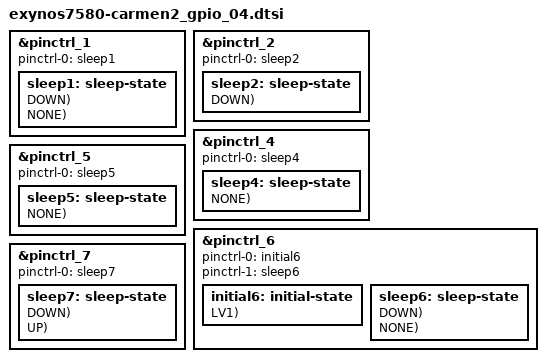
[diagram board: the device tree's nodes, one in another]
/*
 * Copyright (c) 2014 Samsung Electronics Co., Ltd.
 *		http://www.samsung.com
 *
 * This program is free software; you can redistribute it and/or modify
 * it under the terms of the GNU General Public License version 2 as
 * published by the Free Software Foundation.
*/

// Support Carmen2 HW REV02 (b0010)

#include "exynos_gpio_config_macros.dtsi"

// 0x110B0000(AUD): gpz0 ~ gpz3
&pinctrl_1 {
	pinctrl-names = "sleep";
	pinctrl-0 = <&sleep1>;
	sleep1: sleep-state {
		PIN_SLP(gpz0-0, INPUT, DOWN);	/* BT_PCM_SYNC */
		PIN_SLP(gpz0-1, INPUT, DOWN);	/* BT_PCM_CLK */
		PIN_SLP(gpz0-2, INPUT, DOWN);	/* BT_PCM_RXD */
		PIN_SLP(gpz0-3, INPUT, DOWN);	/* BT_PCM_TXD */

		PIN_SLP(gpz1-0, OUT1, NONE);	/* BT_UART_TXD */
		PIN_SLP(gpz1-1, INPUT, NONE);	/* BT_UART_RXD */
		PIN_SLP(gpz1-2, INPUT, NONE);	/* BT_UART_CTS */
		PIN_SLP(gpz1-3, OUT1, NONE);	/* BT_UART_RTS */

		PIN_SLP(gpz2-0, INPUT, DOWN);	/* 2MIC_PCM_SYNC */
		PIN_SLP(gpz2-1, INPUT, DOWN);	/* 2MIC_PCM_CLK */
		PIN_SLP(gpz2-2, INPUT, DOWN);	/* 2MIC_AP_PCM_DI */
		PIN_SLP(gpz2-3, INPUT, DOWN);	/* 2MIC_AP_PCM_DO */

		PIN_SLP(gpz3-0, INPUT, DOWN);	/* NC */
		PIN_SLP(gpz3-1, INPUT, DOWN);	/* NC */
		PIN_SLP(gpz3-2, INPUT, DOWN);	/* 2MIC_CLK_24.576MHZ */
		PIN_SLP(gpz3-3, INPUT, DOWN);	/* NC */
	};
};

// 0x138E0000(ESE): gpc0
&pinctrl_2 {
	pinctrl-names = "sleep";
	pinctrl-0 = <&sleep2>;
	sleep2: sleep-state {
		PIN_SLP(gpc0-0, INPUT, DOWN);	/* BTP_SPI_CLK */
		PIN_SLP(gpc0-1, INPUT, DOWN);	/* BTP_SPI_CS_N */
		PIN_SLP(gpc0-2, INPUT, DOWN);	/* BTP_SPI_MISO */
		PIN_SLP(gpc0-3, INPUT, DOWN);	/* BTP_SPI_MOSI */
	};
};

// 0x104E0000(MIF): gpm0
&pinctrl_4 {
	pinctrl-names = "sleep";
	pinctrl-0 = <&sleep4>;
	sleep4: sleep-state {
		PIN_SLP(gpm0-0, INPUT, NONE);	/* PMIC_SCL_1P8 */
		PIN_SLP(gpm0-1, INPUT, NONE);	/* PMIC_SDA_1P8 */
	};
};

// 0x138C0000(NFC): gpc3
&pinctrl_5 {
	pinctrl-names = "sleep";
	pinctrl-0 = <&sleep5>;
	sleep5: sleep-state {
		PIN_SLP(gpc3-0, INPUT, NONE);	/* NFC_SCL_1P8 */
		PIN_SLP(gpc3-1, INPUT, NONE);	/* NFC_SDA_1P8 */
		PIN_SLP(gpc3-2, PREV, NONE);	/* NFC_EN */
		PIN_SLP(gpc3-3, PREV, NONE);	/* NFC_CLK_REQ */
	};
};

// 0x139C0000(TOP): gpb0~2, gpc1~2, gpc5, gpd0~3, gpe0~1, gpf0~2, etc0
&pinctrl_6 {
	pinctrl-names = "default","sleep";
	pinctrl-0 = <&initial6>;
	pinctrl-1 = <&sleep6>;
	initial6: initial-state {
		PIN_IN(gpd0-0, NONE, LV1);	/* HW_REV0 */
		PIN_IN(gpd0-1, NONE, LV1);	/* HW_REV1 */
		PIN_IN(gpd0-2, NONE, LV1);	/* HW_REV2 */
		PIN_IN(gpd0-3, NONE, LV1);	/* HW_REV3 */
		PIN_OUT_SET(gpd0-5, 0, LV1);    /* LDO26_EN */
	};
	sleep6: sleep-state {
		PIN_SLP(gpb0-0, INPUT, DOWN);	/* AP_UART_RXD */
		PIN_SLP(gpb0-1, INPUT, DOWN);	/* AP_UART_TXD */
		PIN_SLP(gpb0-2, PREV, NONE);	/* SVC_LED_SDA_1P8 */
		PIN_SLP(gpb0-3, PREV, NONE);	/* SVC_LED_SCL_1P8 */
		PIN_SLP(gpb0-4, INPUT, NONE);	/* GPS_RXD */
		PIN_SLP(gpb0-5, OUT0, NONE);	/* GPS_TXD */
		PIN_SLP(gpb0-6, INPUT, NONE);	/* GPS_CTS */
		PIN_SLP(gpb0-7, OUT1, NONE);	/* GPS_RTS */

		PIN_SLP(gpb1-0, INPUT, DOWN);	/* HEALTH_UART_RXD */
		PIN_SLP(gpb1-1, INPUT, DOWN);	/* HEALTH_UART_TXD */

		PIN_SLP(gpb2-0, INPUT, NONE);	/* SHUB_SPI_CLK */
		PIN_SLP(gpb2-1, INPUT, NONE);	/* SHUB_SPI_SS_N */
		PIN_SLP(gpb2-2, INPUT, NONE);	/* SHUB_SPI_MISO */
		PIN_SLP(gpb2-3, INPUT, NONE);	/* SHUB_SPI_MOSI */
		PIN_SLP(gpb2-4, INPUT, DOWN);	/* NC */
		PIN_SLP(gpb2-5, INPUT, DOWN);	/* NC */
		PIN_SLP(gpb2-6, INPUT, DOWN);	/* NC */
		PIN_SLP(gpb2-7, OUT1, NONE);	/* IRDA_CTL */

		PIN_SLP(gpc1-0, OUT1, NONE);	/* XBOOTLDO */
		PIN_SLP(gpc1-1, INPUT, DOWN);	/* VIB_PWM */
		PIN_SLP(gpc1-2, INPUT, NONE);	/* COVER_ID */
		PIN_SLP(gpc1-3, INPUT, DOWN);	/* NC */
		PIN_SLP(gpc1-4, INPUT, DOWN);	/* NC */

		PIN_SLP(gpc2-0, INPUT, NONE);	/* 2MIC_SDA_1P8 */
		PIN_SLP(gpc2-1, INPUT, NONE);	/* 2MIC_SCL_1P8 */
		PIN_SLP(gpc2-2, INPUT, DOWN);	/* VTCAM_SDA_1P8 */
		PIN_SLP(gpc2-3, INPUT, DOWN);	/* VTCAM_SCL_1P8 */
		PIN_SLP(gpc2-4, INPUT, NONE);	/* FG_SDA_1P8 */
		PIN_SLP(gpc2-5, INPUT, NONE);	/* FG_SCL_1P8 */

		PIN_SLP(gpc5-0, INPUT, DOWN);	/* Don't use */
		PIN_SLP(gpc5-1, INPUT, DOWN);	/* Don't use */
		PIN_SLP(gpc5-2, INPUT, DOWN);	/* TOUCH_SDA_1P8 */
		PIN_SLP(gpc5-3, INPUT, DOWN);	/* TOUCH_SCL_1P8 */

		PIN_SLP(gpd0-0, INPUT, NONE);	/* HW_REV0 */
		PIN_SLP(gpd0-1, INPUT, NONE);	/* HW_REV1 */
		PIN_SLP(gpd0-2, INPUT, NONE);	/* HW_REV2 */
		PIN_SLP(gpd0-3, INPUT, NONE);	/* HW_REV3 */
		PIN_SLP(gpd0-4, PREV, NONE);	/* DS_DET */
		PIN_SLP(gpd0-5, OUT1, NONE);	/* LDO26_EN */
		PIN_SLP(gpd0-6, INPUT, DOWN);	/* CAM_SENSOR_CORE_EN */
		PIN_SLP(gpd0-7, INPUT, DOWN);	/* TE */

		PIN_SLP(gpd1-0, PREV, NONE);	/* WLAN_PDn */
		PIN_SLP(gpd1-1, INPUT, DOWN);	/* LCD_1P8_EN */
		PIN_SLP(gpd1-2, INPUT, DOWN);	/* OCTA_ID */
		PIN_SLP(gpd1-3, INPUT, DOWN);	/* MLCD_RST */
		PIN_SLP(gpd1-4, INPUT, DOWN);	/* TSP_ID */
		PIN_SLP(gpd1-5, PREV, NONE);	/* BTP_RST_N */
		PIN_SLP(gpd1-6, INPUT, DOWN);	/* BTP_3V3_EN */

		PIN_SLP(gpd2-0, INPUT, NONE);	/* IF_PMIC_SCL_1P8 */
		PIN_SLP(gpd2-1, INPUT, NONE);	/* IF_PMIC_SDA_1P8 */
		PIN_SLP(gpd2-2, PREV, NONE);	/* UART_SEL */
		PIN_SLP(gpd2-3, PREV, NONE);	/* SUB_MIC_BIAS_EN */
		PIN_SLP(gpd2-4, INPUT, DOWN);	/* PCD_INT */
		PIN_SLP(gpd2-6, INPUT, DOWN);	/* GPS_EN */
		PIN_SLP(gpd2-7, PREV, NONE);	/* BTP_OCP_EN */

		PIN_SLP(gpd3-0, INPUT, DOWN);	/* TP4052 */
		PIN_SLP(gpd3-1, INPUT, DOWN);	/* HRM_1P8_EN */
		PIN_SLP(gpd3-2, INPUT, DOWN);	/* BTP_1V8_EN */
		PIN_SLP(gpd3-3, INPUT, NONE);	/* MUIC_SCL_1P8 */
		PIN_SLP(gpd3-4, INPUT, NONE);	/* MUIC_SDA_1P8 */

		PIN_SLP(gpe0-0, PREV, DOWN);	/* NFC_FIRM */
		PIN_SLP(gpe0-1, INPUT, DOWN);	/* FLASH_LED_TORCH */
		PIN_SLP(gpe0-2, INPUT, DOWN);	/* FLASH_LED_STROBE */
		PIN_SLP(gpe0-3, INPUT, DOWN);	/* VTCAM_RST_N */
		PIN_SLP(gpe0-4, INPUT, DOWN);	/* CAM_RST */
		PIN_SLP(gpe0-5, INPUT, DOWN);	/* RGB_G_EN */
		PIN_SLP(gpe0-6, PREV, NONE);	/* CP_RST_N */
		PIN_SLP(gpe0-7, INPUT, DOWN);	/* MOTOR_EN */

		PIN_SLP(gpe1-0, PREV, NONE);	/* PM_WRSTBI */
		PIN_SLP(gpe1-1, INPUT, DOWN);	/* HEALTH_EN */
		PIN_SLP(gpe1-2, INPUT, DOWN);	/* NC */
		PIN_SLP(gpe1-3, INPUT, DOWN);	/* NC */
		PIN_SLP(gpe1-4, INPUT, DOWN);	/* NC */

		PIN_SLP(gpf0-0, INPUT, DOWN);	/* CAM_SDA_1P8 */
		PIN_SLP(gpf0-1, INPUT, DOWN);	/* CAM_SCL_1P8 */
		PIN_SLP(gpf0-2, INPUT, DOWN);	/* VTCAM_SDA_1P8 */
		PIN_SLP(gpf0-3, INPUT, DOWN);	/* VTCAM_SCL_1P8 */
		PIN_SLP(gpf0-4, INPUT, DOWN);	/* NC */

		PIN_SLP(gpf1-0, INPUT, DOWN);	/* NC */
		PIN_SLP(gpf1-1, INPUT, DOWN);	/* NC */
		PIN_SLP(gpf1-2, INPUT, DOWN);	/* NC */
		PIN_SLP(gpf1-3, INPUT, DOWN);	/* NC */
		PIN_SLP(gpf1-4, INPUT, DOWN);	/* MCU_RST_N_1P8 */
		PIN_SLP(gpf1-5, INPUT, DOWN);	/* TA_TOUCH_SENSE */
		PIN_SLP(gpf1-6, PREV, NONE);	/* VOICE_RST_N */
		PIN_SLP(gpf1-7, PREV, NONE);	/* VOICE_WAKE */
	};
};

// 0x138D0000(TOUCH): gpc4
&pinctrl_7 {
	pinctrl-names = "sleep";
	pinctrl-0= <&sleep7>;
	sleep7: sleep-state {
		PIN_SLP(gpc4-0, INPUT, DOWN);	/* TSP_SDA_1P8 */
		PIN_SLP(gpc4-1, INPUT, DOWN);	/* TSP_SCL_1P8 */
		PIN_SLP(gpc4-2, PREV, UP);	/* BT_EN */
	};
};

